VERSION ""

NS_ :

BS_:

BU_: VCU

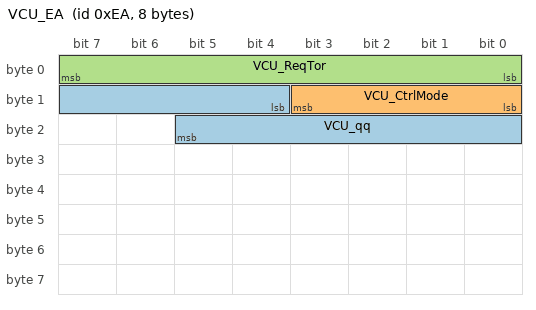
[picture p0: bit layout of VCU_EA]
BO_ 234 VCU_EA: 8 VCU
 SG_ VCU_qq : 12|10@1+ (1,0) [0|1023] "" Vector__XXX
 SG_ VCU_CtrlMode : 8|4@1+ (1,1) [1|16] "" Vector__XXX
 SG_ VCU_ReqTor : 0|8@1+ (0.1,1) [1|26.5] "" Vector__XXX
